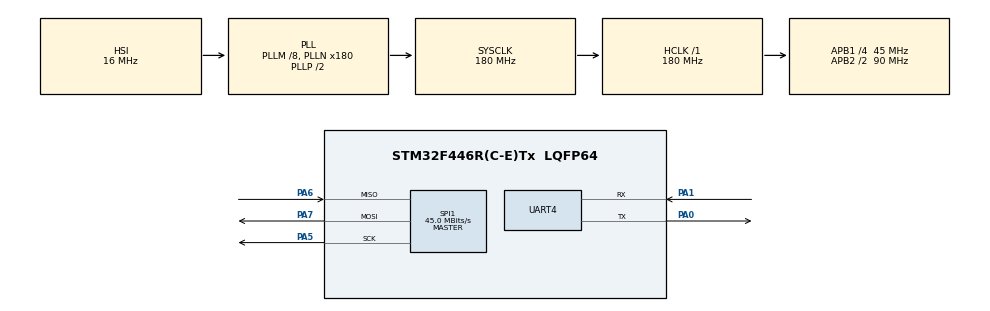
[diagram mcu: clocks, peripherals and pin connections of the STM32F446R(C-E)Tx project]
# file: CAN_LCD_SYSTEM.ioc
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FREERTOS.Tasks01=defaultTask,0,128,StartDefaultTask,Default,NULL,Dynamic,NULL,NULL;CanTask,-2,128,StartCanTask,Default,NULL,Dynamic,NULL,NULL;AppTask,-2,256,StartAppTask,Default,NULL,Dynamic,NULL,NULL
Mcu.Family=STM32F4
Mcu.Name=STM32F446R(C-E)Tx
Mcu.Package=LQFP64
NVIC.PriorityGroup=NVIC_PRIORITYGROUP_4
NVIC.SPI1_IRQn=true\:5\:0\:false\:false\:true\:true\:true\:true\:true
NVIC.UART4_IRQn=true\:5\:0\:false\:false\:true\:true\:true\:true\:true
PA0-WKUP.Mode=Asynchronous
PA0-WKUP.Signal=UART4_TX
PA1.Mode=Asynchronous
PA1.Signal=UART4_RX
PA5.Mode=Full_Duplex_Master
PA5.Signal=SPI1_SCK
PA6.Mode=Full_Duplex_Master
PA6.Signal=SPI1_MISO
PA7.Mode=Full_Duplex_Master
PA7.Signal=SPI1_MOSI
ProjectManager.HeapSize=0x200
ProjectManager.StackSize=0x400
ProjectManager.TargetToolchain=STM32CubeIDE
RCC.AHBFreq_Value=180000000
RCC.APB1CLKDivider=RCC_HCLK_DIV4
RCC.APB1Freq_Value=45000000
RCC.APB1TimFreq_Value=90000000
RCC.APB2CLKDivider=RCC_HCLK_DIV2
RCC.APB2Freq_Value=90000000
RCC.APB2TimFreq_Value=180000000
RCC.CortexFreq_Value=180000000
RCC.HCLKFreq_Value=180000000
RCC.PLLM=8
RCC.PLLN=180
RCC.SYSCLKFreq_VALUE=180000000
RCC.SYSCLKSource=RCC_SYSCLKSOURCE_PLLCLK
RCC.USBFreq_Value=180000000
RCC.VCOOutputFreq_Value=360000000
SPI1.CalculateBaudRate=45.0 MBits/s
SPI1.Direction=SPI_DIRECTION_2LINES
SPI1.Mode=SPI_MODE_MASTER
SPI1.VirtualType=VM_MASTER
UART4.VirtualMode=Asynchronous
VP_FREERTOS_VS_CMSIS_V1.Mode=CMSIS_V1
board=custom

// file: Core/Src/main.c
/* USER CODE BEGIN Header */
/**
  ******************************************************************************
  * @file           : main.c
  * @brief          : Main program body
  ******************************************************************************
  * @attention
  *
  * Copyright (c) 2024 STMicroelectronics.
  * All rights reserved.
  *
  * This software is licensed under terms that can be found in the LICENSE file
  * in the root directory of this software component.
  * If no LICENSE file comes with this software, it is provided AS-IS.
  *
  ******************************************************************************
  */
/* USER CODE END Header */
#include "main.h"
#include "cmsis_os.h"

/* USER CODE BEGIN Includes */
#include "console.h"
#include "usart_drv.h"
/* USER CODE END Includes */

/* USER CODE BEGIN PTD */
typedef osStatus (*INIT_FUNC)(void);
/* USER CODE END PTD */

SPI_HandleTypeDef hspi1;

UART_HandleTypeDef huart4;

osThreadId defaultTaskHandle;
osThreadId CanTaskHandle;
osThreadId AppTaskHandle;
/* USER CODE BEGIN PV */
static const INIT_FUNC init_func[] = {
	// drv
	usart_drv_init,
	// app
	console_init,
};
/* USER CODE END PV */

void SystemClock_Config(void);
static void MX_GPIO_Init(void);
static void MX_SPI1_Init(void);
static void MX_UART4_Init(void);
void StartDefaultTask(void const * argument);
void StartCanTask(void const * argument);
void StartAppTask(void const * argument);

int main(void)
{

  /* USER CODE BEGIN 1 */
	uint8_t i, size;
  /* USER CODE END 1 */

  /* MCU Configuration--------------------------------------------------------*/

  /* Reset of all peripherals, Initializes the Flash interface and the Systick. */
  HAL_Init();

  /* Configure the system clock */
  SystemClock_Config();

  /* Initialize all configured peripherals */
  MX_GPIO_Init();
  MX_SPI1_Init();
  MX_UART4_Init();
  /* USER CODE BEGIN 2 */
	size = sizeof(init_func)/sizeof(init_func[0]);

	for (i = 0; i < size; i++) {
		init_func[i]();
	}
  /* USER CODE END 2 */

  /* Create the thread(s) */
  /* definition and creation of defaultTask */
  osThreadDef(defaultTask, StartDefaultTask, osPriorityNormal, 0, 128);
  defaultTaskHandle = osThreadCreate(osThread(defaultTask), NULL);

  /* definition and creation of CanTask */
  osThreadDef(CanTask, StartCanTask, osPriorityLow, 0, 128);
  CanTaskHandle = osThreadCreate(osThread(CanTask), NULL);

  /* definition and creation of AppTask */
  osThreadDef(AppTask, StartAppTask, osPriorityLow, 0, 256);
  AppTaskHandle = osThreadCreate(osThread(AppTask), NULL);

  /* Start scheduler */
  osKernelStart();

  /* We should never get here as control is now taken by the scheduler */

  /* Infinite loop */
  while (1)
  {

  }
}

void SystemClock_Config(void)
{
  RCC_OscInitTypeDef RCC_OscInitStruct = {0};
  RCC_ClkInitTypeDef RCC_ClkInitStruct = {0};

  /** Configure the main internal regulator output voltage
  */
  __HAL_RCC_PWR_CLK_ENABLE();
  __HAL_PWR_VOLTAGESCALING_CONFIG(PWR_REGULATOR_VOLTAGE_SCALE1);

  /** Initializes the RCC Oscillators according to the specified parameters
  * in the RCC_OscInitTypeDef structure.
  */
  RCC_OscInitStruct.OscillatorType = RCC_OSCILLATORTYPE_HSI;
  RCC_OscInitStruct.HSIState = RCC_HSI_ON;
  RCC_OscInitStruct.HSICalibrationValue = RCC_HSICALIBRATION_DEFAULT;
  RCC_OscInitStruct.PLL.PLLState = RCC_PLL_ON;
  RCC_OscInitStruct.PLL.PLLSource = RCC_PLLSOURCE_HSI;
  RCC_OscInitStruct.PLL.PLLM = 8;
  RCC_OscInitStruct.PLL.PLLN = 180;
  RCC_OscInitStruct.PLL.PLLP = RCC_PLLP_DIV2;
  RCC_OscInitStruct.PLL.PLLQ = 2;
  RCC_OscInitStruct.PLL.PLLR = 2;
  if (HAL_RCC_OscConfig(&RCC_OscInitStruct) != HAL_OK)
  {
    Error_Handler();
  }

  /** Activate the Over-Drive mode
  */
  if (HAL_PWREx_EnableOverDrive() != HAL_OK)
  {
    Error_Handler();
  }

  /** Initializes the CPU, AHB and APB buses clocks
  */
  RCC_ClkInitStruct.ClockType = RCC_CLOCKTYPE_HCLK|RCC_CLOCKTYPE_SYSCLK
                              |RCC_CLOCKTYPE_PCLK1|RCC_CLOCKTYPE_PCLK2;
  RCC_ClkInitStruct.SYSCLKSource = RCC_SYSCLKSOURCE_PLLCLK;
  RCC_ClkInitStruct.AHBCLKDivider = RCC_SYSCLK_DIV1;
  RCC_ClkInitStruct.APB1CLKDivider = RCC_HCLK_DIV4;
  RCC_ClkInitStruct.APB2CLKDivider = RCC_HCLK_DIV2;

  if (HAL_RCC_ClockConfig(&RCC_ClkInitStruct, FLASH_LATENCY_5) != HAL_OK)
  {
    Error_Handler();
  }
}

static void MX_SPI1_Init(void)
{

  /* SPI1 parameter configuration*/
  hspi1.Instance = SPI1;
  hspi1.Init.Mode = SPI_MODE_MASTER;
  hspi1.Init.Direction = SPI_DIRECTION_2LINES;
  hspi1.Init.DataSize = SPI_DATASIZE_8BIT;
  hspi1.Init.CLKPolarity = SPI_POLARITY_LOW;
  hspi1.Init.CLKPhase = SPI_PHASE_1EDGE;
  hspi1.Init.NSS = SPI_NSS_SOFT;
  hspi1.Init.BaudRatePrescaler = SPI_BAUDRATEPRESCALER_2;
  hspi1.Init.FirstBit = SPI_FIRSTBIT_MSB;
  hspi1.Init.TIMode = SPI_TIMODE_DISABLE;
  hspi1.Init.CRCCalculation = SPI_CRCCALCULATION_DISABLE;
  hspi1.Init.CRCPolynomial = 10;
  if (HAL_SPI_Init(&hspi1) != HAL_OK)
  {
    Error_Handler();
  }

}

static void MX_UART4_Init(void)
{

  huart4.Instance = UART4;
  huart4.Init.BaudRate = 115200;
  huart4.Init.WordLength = UART_WORDLENGTH_8B;
  huart4.Init.StopBits = UART_STOPBITS_1;
  huart4.Init.Parity = UART_PARITY_NONE;
  huart4.Init.Mode = UART_MODE_TX_RX;
  huart4.Init.HwFlowCtl = UART_HWCONTROL_NONE;
  huart4.Init.OverSampling = UART_OVERSAMPLING_16;
  if (HAL_UART_Init(&huart4) != HAL_OK)
  {
    Error_Handler();
  }

}

static void MX_GPIO_Init(void)
{

  /* GPIO Ports Clock Enable */
  __HAL_RCC_GPIOA_CLK_ENABLE();

}

void StartDefaultTask(void const * argument)
{
  for(;;)
  {
    osDelay(1);
  }
}

void StartCanTask(void const * argument)
{
  for(;;)
  {
    osDelay(1);
  }
}

void StartAppTask(void const * argument)
{
  for(;;)
  {
    osDelay(1);
  }
}

void Error_Handler(void)
{
  __disable_irq();
  while (1)
  {
  }
}
